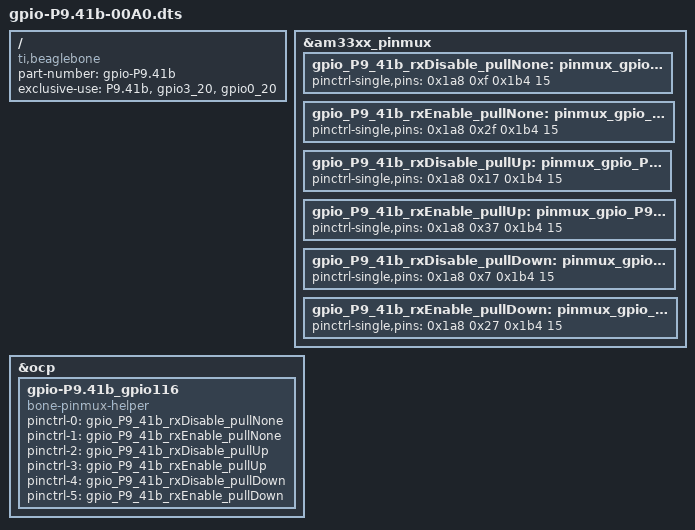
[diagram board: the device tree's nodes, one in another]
/*
* Easy gpio mux control of "P9.41b" ("gpio3_20", "gpio0_20")
*/
/dts-v1/;
/plugin/;

/ {
	compatible = "ti,beaglebone", "ti,beaglebone-black";

	/* identification */
	part-number = "gpio-P9.41b";
	/* version = "00A0"; */

	/* state the resources this cape uses */
	exclusive-use =
		/* the pin header uses */
		"P9.41b",

		/* the hardware IP uses */
		"gpio3_20", "gpio0_20";
	
	
	/* rxDisable_pullNone state */
	fragment@0 {
		target = <&am33xx_pinmux>;
		__overlay__ {
			gpio_P9_41b_rxDisable_pullNone: pinmux_gpio_P9.41b_rxDisable_pullNone {
				pinctrl-single,pins = <
					0x1a8 0xf	0x1b4 15
				>;
			};
		};
	};

	/* rxEnable_pullNone state */
	fragment@1 {
		target = <&am33xx_pinmux>;
		__overlay__ {
			gpio_P9_41b_rxEnable_pullNone: pinmux_gpio_P9.41b_rxEnable_pullNone {
				pinctrl-single,pins = <
					0x1a8 0x2f	0x1b4 15
				>;
			};
		};
	};

	/* rxDisable_pullUp state */
	fragment@2 {
		target = <&am33xx_pinmux>;
		__overlay__ {
			gpio_P9_41b_rxDisable_pullUp: pinmux_gpio_P9.41b_rxDisable_pullUp {
				pinctrl-single,pins = <
					0x1a8 0x17	0x1b4 15
				>;
			};
		};
	};

	/* rxEnable_pullUp state */
	fragment@3 {
		target = <&am33xx_pinmux>;
		__overlay__ {
			gpio_P9_41b_rxEnable_pullUp: pinmux_gpio_P9.41b_rxEnable_pullUp {
				pinctrl-single,pins = <
					0x1a8 0x37	0x1b4 15
				>;
			};
		};
	};

	/* rxDisable_pullDown state */
	fragment@4 {
		target = <&am33xx_pinmux>;
		__overlay__ {
			gpio_P9_41b_rxDisable_pullDown: pinmux_gpio_P9.41b_rxDisable_pullDown {
				pinctrl-single,pins = <
					0x1a8 0x7	0x1b4 15
				>;
			};
		};
	};

	/* rxEnable_pullDown state */
	fragment@5 {
		target = <&am33xx_pinmux>;
		__overlay__ {
			gpio_P9_41b_rxEnable_pullDown: pinmux_gpio_P9.41b_rxEnable_pullDown {
				pinctrl-single,pins = <
					0x1a8 0x27	0x1b4 15
				>;
			};
		};
	};

	fragment@6 {
		target = <&ocp>;
		__overlay__ {
			gpio-P9.41b_gpio116 {
				compatible = "bone-pinmux-helper";
				status = "okay";
				pinctrl-names = "rxDisable_pullNone", "rxEnable_pullNone", "rxDisable_pullUp", "rxEnable_pullUp", "rxDisable_pullDown", "rxEnable_pullDown";
				pinctrl-0 = <&gpio_P9_41b_rxDisable_pullNone>;
				pinctrl-1 = <&gpio_P9_41b_rxEnable_pullNone>;
				pinctrl-2 = <&gpio_P9_41b_rxDisable_pullUp>;
				pinctrl-3 = <&gpio_P9_41b_rxEnable_pullUp>;
				pinctrl-4 = <&gpio_P9_41b_rxDisable_pullDown>;
				pinctrl-5 = <&gpio_P9_41b_rxEnable_pullDown>;
			};
		};
	};

};
